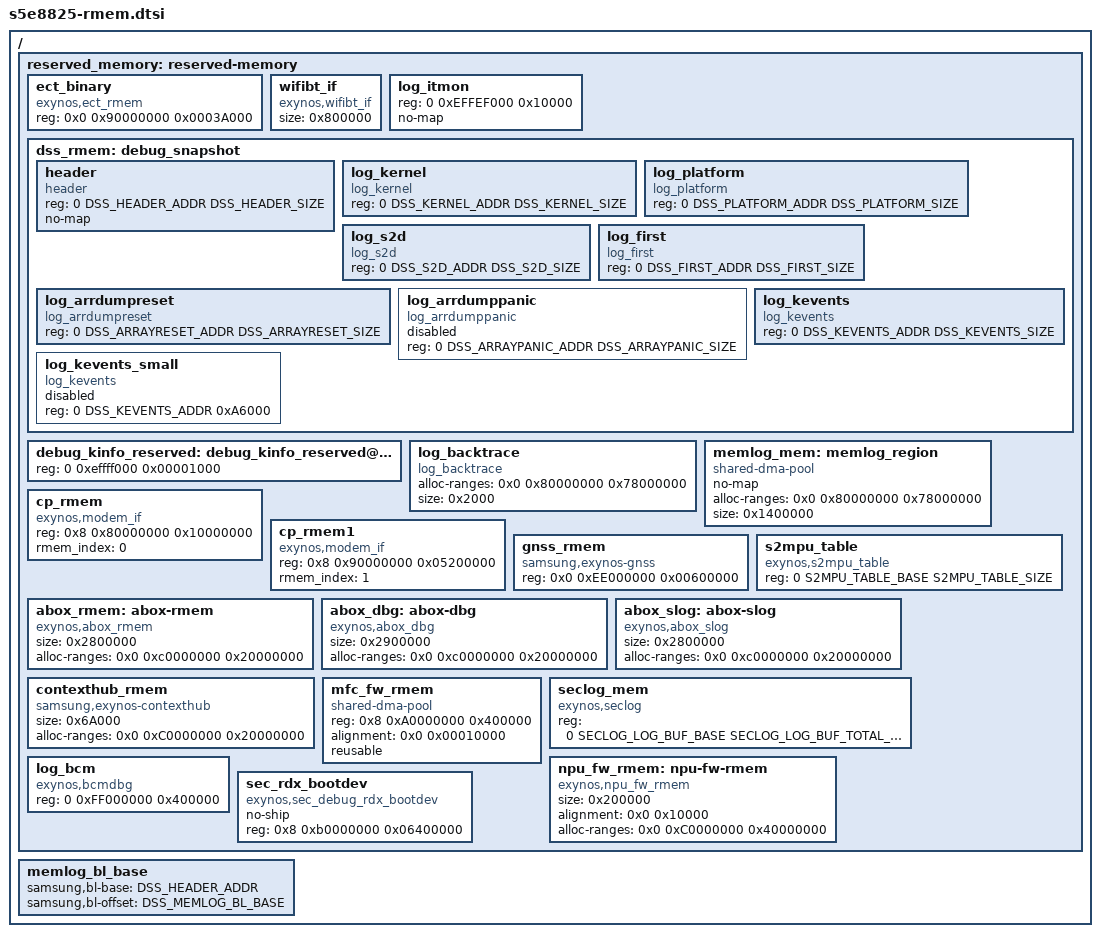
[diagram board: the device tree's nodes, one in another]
/*
 * SAMSUNG EXYNOS device tree source for reserved-memory
 *
 * Copyright (c) 2015 Samsung Electronics Co., Ltd.
 *             http://www.samsung.com
 *
 * This program is free software; you can redistribute it and/or modify
 * it under the terms of the GNU General Public License version 2 as
 * published by the Free Software Foundation.
 */

#include <dt-bindings/soc/samsung/s5e8825-debug.h>
#include <dt-bindings/soc/samsung/s5e8825-s2mpu.h>
#include <dt-bindings/soc/samsung/s5e8825-seclog.h>

/ {
	reserved_memory: reserved-memory {
		#address-cells = <2>;
		#size-cells = <1>;
		ranges;

		ect_binary: ect_binary {
			compatible = "exynos,ect_rmem";
			reg = <0x0 0x90000000 0x0003A000>;
		};

		wifibt_if: wifibt_if {
			compatible = "exynos,wifibt_if";
			size = <0x800000>;
		};

		log_itmon: log_itmon {
			reg = <0 0xEFFEF000 0x10000>;
			no-map;
		};

		dss_rmem: debug_snapshot {
			#address-cells = <2>;
			#size-cells = <1>;
			header: header {
				compatible = "header";
				reg = <0 DSS_HEADER_ADDR DSS_HEADER_SIZE>;
				no-map;
			};
			log_kernel: log_kernel {
				compatible = "log_kernel";
				reg = <0 DSS_KERNEL_ADDR DSS_KERNEL_SIZE>;
			};
			log_platform: log_platform {
				compatible = "log_platform";
				reg = <0 DSS_PLATFORM_ADDR DSS_PLATFORM_SIZE>;
			};
			log_s2d: log_s2d {
				compatible = "log_s2d";
				reg = <0 DSS_S2D_ADDR DSS_S2D_SIZE>;
			};
			log_first: log_first {
				compatible = "log_first";
				reg = <0 DSS_FIRST_ADDR DSS_FIRST_SIZE>;
			};
			log_arrdumpreset: log_arrdumpreset {
				compatible = "log_arrdumpreset";
				reg = <0 DSS_ARRAYRESET_ADDR DSS_ARRAYRESET_SIZE>;
			};
			log_arrdumppanic: log_arrdumppanic {
				compatible = "log_arrdumppanic";
				reg = <0 DSS_ARRAYPANIC_ADDR DSS_ARRAYPANIC_SIZE>;
				status = "no";
			};
			log_kevents: log_kevents {
				compatible = "log_kevents";
				reg = <0 DSS_KEVENTS_ADDR DSS_KEVENTS_SIZE>;
			};
			log_kevents_small: log_kevents_small {
				compatible = "log_kevents";
				reg = <0 DSS_KEVENTS_ADDR 0xA6000>;
				status = "no";
			};
		};

		debug_kinfo_reserved: debug_kinfo_reserved@effff000 {
			reg = <0 0xeffff000 0x00001000>;
		};

		log_backtrace: log_backtrace {
			compatible = "log_backtrace";
			alloc-ranges = <0x0 0x80000000 0x78000000>;
			size = <0x2000>;
		};

		memlog_mem: memlog_region {
			compatible = "shared-dma-pool";
			no-map;
			alloc-ranges = <0x0 0x80000000 0x78000000>;
			size = <0x1400000>;
		};

		cp_rmem: cp_rmem {
			compatible = "exynos,modem_if";
			reg = <0x8 0x80000000 0x10000000>;
			rmem_index = <0>;
		};

		cp_rmem1: cp_rmem1 {
			compatible = "exynos,modem_if";
			reg = <0x8 0x90000000 0x05200000>;
			rmem_index = <1>;
		};

		gnss_rmem: gnss_rmem {
			compatible = "samsung,exynos-gnss";
			reg = <0x0 0xEE000000 0x00600000>;
		};

		s2mpu_table: s2mpu_table {
			compatible = "exynos,s2mpu_table";
			reg = <0 S2MPU_TABLE_BASE S2MPU_TABLE_SIZE>;
		};

		abox_rmem: abox-rmem {
			compatible = "exynos,abox_rmem";
			/* Size should be same with
			* CONFIG_SND_SOC_SAMSUNG_ABOX_DRAM_SIZE.
			*/
			size = <0x2800000>;
			alloc-ranges = <0x0 0xc0000000 0x20000000>;
		};

		abox_dbg: abox-dbg {
			compatible = "exynos,abox_dbg";
			size = <0x2900000>;
			alloc-ranges = <0x0 0xc0000000 0x20000000>;
		};

		abox_slog: abox-slog {
			compatible = "exynos,abox_slog";
			size = <0x2800000>;
			alloc-ranges = <0x0 0xc0000000 0x20000000>;
		};

		contexthub_rmem: contexthub_rmem {
			compatible = "samsung,exynos-contexthub";
			size = <0x6A000>;
			alloc-ranges = <0x0 0xC0000000 0x20000000>;
		};

		mfc_fw_rmem: mfc_fw_rmem {
			compatible = "shared-dma-pool";
			reg = <0x8 0xA0000000 0x400000>;
			alignment = <0x0 0x00010000>;
			reusable;
		};

		seclog_mem: seclog_mem {
			compatible = "exynos,seclog";
			reg = <0 SECLOG_LOG_BUF_BASE SECLOG_LOG_BUF_TOTAL_SIZE>;
		};

		log_bcm: log_bcm {
			compatible = "exynos,bcmdbg";
			reg = <0 0xFF000000 0x400000>;
		};

		npu_fw_rmem: npu-fw-rmem {
			compatible = "exynos,npu_fw_rmem";
			size = <0x200000>;
			alignment = <0x0 0x10000>;
			alloc-ranges = <0x0 0xC0000000 0x40000000>;
		};

		/* fb_handover shall be removed in DPU command mode
		 * operation. Otherwise, It will end up in waste of memory
		 */
/*		fb_handover: fb_handover {
			compatible = "exynos,fb_handover";
			reg = <0x0 0xFA000000 0x03C00000>;
		};
*/
		
		
		sec_rdx_bootdev {
			compatible = "exynos,sec_debug_rdx_bootdev";
			no-ship;
			reg = <0x8 0xb0000000 0x06400000>;
		};			
	};

	memlog_bl_base: memlog_bl_base {
		samsung,bl-base = <DSS_HEADER_ADDR>;
		samsung,bl-offset = <DSS_MEMLOG_BL_BASE>;
	};

};
